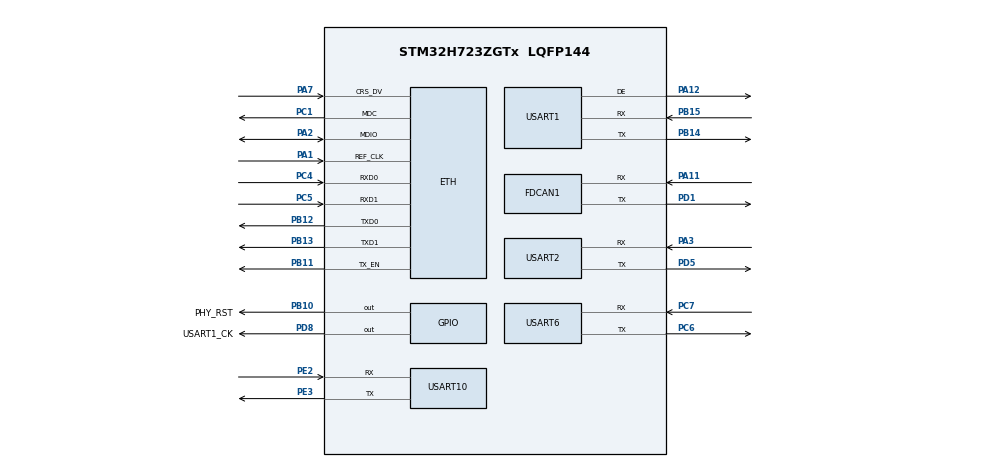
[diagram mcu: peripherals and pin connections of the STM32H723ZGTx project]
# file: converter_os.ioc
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CORTEX_M7.AccessPermission-Cortex_Memory_Protection_Unit_Region0_Settings=MPU_REGION_FULL_ACCESS
CORTEX_M7.AccessPermission-Cortex_Memory_Protection_Unit_Region1_Settings=MPU_REGION_FULL_ACCESS
CORTEX_M7.BaseAddress-Cortex_Memory_Protection_Unit_Region0_Settings=0x30000000
CORTEX_M7.BaseAddress-Cortex_Memory_Protection_Unit_Region1_Settings=0x30000000
CORTEX_M7.CPU_DCache=Enabled
CORTEX_M7.CPU_ICache=Enabled
CORTEX_M7.DisableExec-Cortex_Memory_Protection_Unit_Region0_Settings=MPU_INSTRUCTION_ACCESS_ENABLE
CORTEX_M7.Enable-Cortex_Memory_Protection_Unit_Region0_Settings=MPU_REGION_ENABLE
CORTEX_M7.Enable-Cortex_Memory_Protection_Unit_Region1_Settings=MPU_REGION_ENABLE
CORTEX_M7.Enable-Cortex_Memory_Protection_Unit_Region2_Settings=__NULL
CORTEX_M7.IsBufferable-Cortex_Memory_Protection_Unit_Region1_Settings=MPU_ACCESS_BUFFERABLE
CORTEX_M7.IsCacheable-Cortex_Memory_Protection_Unit_Region0_Settings=MPU_ACCESS_CACHEABLE
CORTEX_M7.IsCacheable-Cortex_Memory_Protection_Unit_Region1_Settings=MPU_ACCESS_NOT_CACHEABLE
CORTEX_M7.IsShareable-Cortex_Memory_Protection_Unit_Region0_Settings=MPU_ACCESS_NOT_SHAREABLE
CORTEX_M7.MPU_Control=MPU_PRIVILEGED_DEFAULT
CORTEX_M7.Size-Cortex_Memory_Protection_Unit_Region0_Settings=MPU_REGION_SIZE_32KB
CORTEX_M7.Size-Cortex_Memory_Protection_Unit_Region1_Settings=MPU_REGION_SIZE_256B
CORTEX_M7.SubRegionDisable-Cortex_Memory_Protection_Unit_Region0_Settings=0
CORTEX_M7.default_mode_Activation=0
Dma.Request0=USART10_RX
Dma.Request1=USART10_TX
Dma.Request2=USART1_RX
Dma.Request3=USART1_TX
Dma.Request4=USART2_RX
Dma.Request5=USART2_TX
Dma.Request6=USART6_RX
Dma.Request7=USART6_TX
Dma.USART10_RX.0.Direction=DMA_PERIPH_TO_MEMORY
Dma.USART10_RX.0.EventEnable=DISABLE
Dma.USART10_RX.0.FIFOMode=DMA_FIFOMODE_DISABLE
Dma.USART10_RX.0.Instance=DMA1_Stream0
Dma.USART10_RX.0.MemDataAlignment=DMA_MDATAALIGN_BYTE
Dma.USART10_RX.0.MemInc=DMA_MINC_ENABLE
Dma.USART10_RX.0.Mode=DMA_CIRCULAR
Dma.USART10_RX.0.PeriphDataAlignment=DMA_PDATAALIGN_BYTE
Dma.USART10_RX.0.PeriphInc=DMA_PINC_DISABLE
Dma.USART10_RX.0.Polarity=HAL_DMAMUX_REQ_GEN_RISING
Dma.USART10_RX.0.Priority=DMA_PRIORITY_LOW
Dma.USART10_RX.0.RequestNumber=1
Dma.USART10_RX.0.SignalID=NONE
Dma.USART10_RX.0.SyncEnable=DISABLE
Dma.USART10_RX.0.SyncPolarity=HAL_DMAMUX_SYNC_NO_EVENT
Dma.USART10_RX.0.SyncRequestNumber=1
Dma.USART10_RX.0.SyncSignalID=NONE
Dma.USART10_TX.1.Direction=DMA_MEMORY_TO_PERIPH
Dma.USART10_TX.1.EventEnable=DISABLE
Dma.USART10_TX.1.FIFOMode=DMA_FIFOMODE_DISABLE
Dma.USART10_TX.1.Instance=DMA1_Stream1
Dma.USART10_TX.1.MemDataAlignment=DMA_MDATAALIGN_BYTE
Dma.USART10_TX.1.MemInc=DMA_MINC_ENABLE
Dma.USART10_TX.1.Mode=DMA_NORMAL
Dma.USART10_TX.1.PeriphDataAlignment=DMA_PDATAALIGN_BYTE
Dma.USART10_TX.1.PeriphInc=DMA_PINC_DISABLE
Dma.USART10_TX.1.Polarity=HAL_DMAMUX_REQ_GEN_RISING
Dma.USART10_TX.1.Priority=DMA_PRIORITY_LOW
Dma.USART10_TX.1.RequestNumber=1
Dma.USART10_TX.1.SignalID=NONE
Dma.USART10_TX.1.SyncEnable=DISABLE
Dma.USART10_TX.1.SyncPolarity=HAL_DMAMUX_SYNC_NO_EVENT
Dma.USART10_TX.1.SyncRequestNumber=1
Dma.USART10_TX.1.SyncSignalID=NONE
Dma.USART1_RX.2.Direction=DMA_PERIPH_TO_MEMORY
Dma.USART1_RX.2.EventEnable=DISABLE
Dma.USART1_RX.2.FIFOMode=DMA_FIFOMODE_DISABLE
Dma.USART1_RX.2.Instance=DMA1_Stream2
Dma.USART1_RX.2.MemDataAlignment=DMA_MDATAALIGN_BYTE
Dma.USART1_RX.2.MemInc=DMA_MINC_ENABLE
Dma.USART1_RX.2.Mode=DMA_CIRCULAR
Dma.USART1_RX.2.PeriphDataAlignment=DMA_PDATAALIGN_BYTE
Dma.USART1_RX.2.PeriphInc=DMA_PINC_DISABLE
Dma.USART1_RX.2.Polarity=HAL_DMAMUX_REQ_GEN_RISING
Dma.USART1_RX.2.Priority=DMA_PRIORITY_LOW
Dma.USART1_RX.2.RequestNumber=1
Dma.USART1_RX.2.SignalID=NONE
Dma.USART1_RX.2.SyncEnable=DISABLE
Dma.USART1_RX.2.SyncPolarity=HAL_DMAMUX_SYNC_NO_EVENT
Dma.USART1_RX.2.SyncRequestNumber=1
Dma.USART1_RX.2.SyncSignalID=NONE
Dma.USART1_TX.3.Direction=DMA_MEMORY_TO_PERIPH
Dma.USART1_TX.3.EventEnable=DISABLE
Dma.USART1_TX.3.FIFOMode=DMA_FIFOMODE_DISABLE
Dma.USART1_TX.3.Instance=DMA1_Stream3
Dma.USART1_TX.3.MemDataAlignment=DMA_MDATAALIGN_BYTE
Dma.USART1_TX.3.MemInc=DMA_MINC_ENABLE
Dma.USART1_TX.3.Mode=DMA_NORMAL
Dma.USART1_TX.3.PeriphDataAlignment=DMA_PDATAALIGN_BYTE
Dma.USART1_TX.3.PeriphInc=DMA_PINC_DISABLE
Dma.USART1_TX.3.Polarity=HAL_DMAMUX_REQ_GEN_RISING
Dma.USART1_TX.3.Priority=DMA_PRIORITY_LOW
Dma.USART1_TX.3.RequestNumber=1
Dma.USART1_TX.3.SignalID=NONE
Dma.USART1_TX.3.SyncEnable=DISABLE
Dma.USART1_TX.3.SyncPolarity=HAL_DMAMUX_SYNC_NO_EVENT
Dma.USART1_TX.3.SyncRequestNumber=1
Dma.USART1_TX.3.SyncSignalID=NONE
Dma.USART2_RX.4.Direction=DMA_PERIPH_TO_MEMORY
Dma.USART2_RX.4.EventEnable=DISABLE
Dma.USART2_RX.4.FIFOMode=DMA_FIFOMODE_DISABLE
Dma.USART2_RX.4.Instance=DMA1_Stream4
Dma.USART2_RX.4.MemDataAlignment=DMA_MDATAALIGN_BYTE
Dma.USART2_RX.4.MemInc=DMA_MINC_ENABLE
Dma.USART2_RX.4.Mode=DMA_CIRCULAR
Dma.USART2_RX.4.PeriphDataAlignment=DMA_PDATAALIGN_BYTE
Dma.USART2_RX.4.PeriphInc=DMA_PINC_DISABLE
Dma.USART2_RX.4.Polarity=HAL_DMAMUX_REQ_GEN_RISING
Dma.USART2_RX.4.Priority=DMA_PRIORITY_LOW
Dma.USART2_RX.4.RequestNumber=1
Dma.USART2_RX.4.SignalID=NONE
Dma.USART2_RX.4.SyncEnable=DISABLE
Dma.USART2_RX.4.SyncPolarity=HAL_DMAMUX_SYNC_NO_EVENT
Dma.USART2_RX.4.SyncRequestNumber=1
Dma.USART2_RX.4.SyncSignalID=NONE
Dma.USART2_TX.5.Direction=DMA_MEMORY_TO_PERIPH
Dma.USART2_TX.5.EventEnable=DISABLE
Dma.USART2_TX.5.FIFOMode=DMA_FIFOMODE_DISABLE
Dma.USART2_TX.5.Instance=DMA1_Stream5
Dma.USART2_TX.5.MemDataAlignment=DMA_MDATAALIGN_BYTE
Dma.USART2_TX.5.MemInc=DMA_MINC_ENABLE
Dma.USART2_TX.5.Mode=DMA_NORMAL
Dma.USART2_TX.5.PeriphDataAlignment=DMA_PDATAALIGN_BYTE
Dma.USART2_TX.5.PeriphInc=DMA_PINC_DISABLE
Dma.USART2_TX.5.Polarity=HAL_DMAMUX_REQ_GEN_RISING
Dma.USART2_TX.5.Priority=DMA_PRIORITY_LOW
Dma.USART2_TX.5.RequestNumber=1
Dma.USART2_TX.5.SignalID=NONE
Dma.USART2_TX.5.SyncEnable=DISABLE
Dma.USART2_TX.5.SyncPolarity=HAL_DMAMUX_SYNC_NO_EVENT
Dma.USART2_TX.5.SyncRequestNumber=1
Dma.USART2_TX.5.SyncSignalID=NONE
Dma.USART6_RX.6.Direction=DMA_PERIPH_TO_MEMORY
Dma.USART6_RX.6.EventEnable=DISABLE
Dma.USART6_RX.6.FIFOMode=DMA_FIFOMODE_DISABLE
Dma.USART6_RX.6.Instance=DMA1_Stream6
Dma.USART6_RX.6.MemDataAlignment=DMA_MDATAALIGN_BYTE
Dma.USART6_RX.6.MemInc=DMA_MINC_ENABLE
Dma.USART6_RX.6.Mode=DMA_CIRCULAR
Dma.USART6_RX.6.PeriphDataAlignment=DMA_PDATAALIGN_BYTE
Dma.USART6_RX.6.PeriphInc=DMA_PINC_DISABLE
Dma.USART6_RX.6.Polarity=HAL_DMAMUX_REQ_GEN_RISING
Dma.USART6_RX.6.Priority=DMA_PRIORITY_LOW
Dma.USART6_RX.6.RequestNumber=1
Dma.USART6_RX.6.SignalID=NONE
Dma.USART6_RX.6.SyncEnable=DISABLE
Dma.USART6_RX.6.SyncPolarity=HAL_DMAMUX_SYNC_NO_EVENT
Dma.USART6_RX.6.SyncRequestNumber=1
Dma.USART6_RX.6.SyncSignalID=NONE
Dma.USART6_TX.7.Direction=DMA_MEMORY_TO_PERIPH
Dma.USART6_TX.7.EventEnable=DISABLE
Dma.USART6_TX.7.FIFOMode=DMA_FIFOMODE_DISABLE
Dma.USART6_TX.7.Instance=DMA1_Stream7
Dma.USART6_TX.7.MemDataAlignment=DMA_MDATAALIGN_BYTE
Dma.USART6_TX.7.MemInc=DMA_MINC_ENABLE
Dma.USART6_TX.7.Mode=DMA_NORMAL
Dma.USART6_TX.7.PeriphDataAlignment=DMA_PDATAALIGN_BYTE
Dma.USART6_TX.7.PeriphInc=DMA_PINC_DISABLE
Dma.USART6_TX.7.Polarity=HAL_DMAMUX_REQ_GEN_RISING
Dma.USART6_TX.7.Priority=DMA_PRIORITY_LOW
Dma.USART6_TX.7.RequestNumber=1
Dma.USART6_TX.7.SignalID=NONE
Dma.USART6_TX.7.SyncEnable=DISABLE
Dma.USART6_TX.7.SyncPolarity=HAL_DMAMUX_SYNC_NO_EVENT
Dma.USART6_TX.7.SyncRequestNumber=1
Dma.USART6_TX.7.SyncSignalID=NONE
ETH.MediaInterface=HAL_ETH_RMII_MODE
FDCAN1.CalculateBaudRateNominal=500000
FDCAN1.CalculateTimeBitNominal=2000
FDCAN1.CalculateTimeQuantumNominal=38.46153846153846
FDCAN1.DataPrescaler=5
FDCAN1.DataSyncJumpWidth=12
FDCAN1.DataTimeSeg1=32
FDCAN1.DataTimeSeg2=16
FDCAN1.NominalPrescaler=5
FDCAN1.NominalSyncJumpWidth=12
FDCAN1.NominalTimeSeg1=39
FDCAN1.NominalTimeSeg2=12
FDCAN1.RxFifo0ElmtsNbr=32
FDCAN1.RxFifo1ElmtsNbr=32
FDCAN1.StdFiltersNbr=1
FDCAN1.TxFifoQueueElmtsNbr=6
Mcu.Family=STM32H7
Mcu.Name=STM32H723ZGTx
Mcu.Package=LQFP144
NVIC.DMA1_Stream0_IRQn=true\:0\:0\:false\:false\:true\:false\:true\:true
NVIC.DMA1_Stream1_IRQn=true\:0\:0\:false\:false\:true\:false\:true\:true
NVIC.DMA1_Stream2_IRQn=true\:0\:0\:false\:false\:true\:false\:true\:true
NVIC.DMA1_Stream3_IRQn=true\:0\:0\:false\:false\:true\:false\:true\:true
NVIC.DMA1_Stream4_IRQn=true\:0\:0\:false\:false\:true\:false\:true\:true
NVIC.DMA1_Stream5_IRQn=true\:0\:0\:false\:false\:true\:false\:true\:true
NVIC.DMA1_Stream6_IRQn=true\:0\:0\:false\:false\:true\:false\:true\:true
NVIC.DMA1_Stream7_IRQn=true\:0\:0\:false\:false\:true\:false\:true\:true
NVIC.ETH_IRQn=true\:0\:0\:false\:false\:true\:true\:true\:true
NVIC.FDCAN1_IT0_IRQn=true\:0\:0\:false\:false\:true\:true\:true\:true
NVIC.FDCAN1_IT1_IRQn=true\:0\:0\:false\:false\:true\:true\:true\:true
NVIC.PriorityGroup=NVIC_PRIORITYGROUP_4
NVIC.TIM2_IRQn=true\:0\:0\:false\:false\:true\:true\:true\:true
NVIC.TIM6_DAC_IRQn=true\:15\:0\:false\:false\:true\:false\:true\:true
NVIC.TimeBase=TIM6_DAC_IRQn
NVIC.TimeBaseIP=TIM6
NVIC.USART10_IRQn=true\:0\:0\:false\:false\:true\:true\:true\:true
NVIC.USART1_IRQn=true\:0\:0\:false\:false\:true\:true\:true\:true
NVIC.USART2_IRQn=true\:0\:0\:false\:false\:true\:true\:true\:true
NVIC.USART6_IRQn=true\:0\:0\:false\:false\:true\:true\:true\:true
PA1.GPIO_Speed=GPIO_SPEED_FREQ_VERY_HIGH
PA1.Mode=RMII
PA1.Signal=ETH_REF_CLK
PA11.Mode=FDCAN_Activate
PA11.Signal=FDCAN1_RX
PA12.Mode=Hardware Flow Control (RS485)
PA12.Signal=USART1_DE
PA2.GPIO_Speed=GPIO_SPEED_FREQ_VERY_HIGH
PA2.Mode=RMII
PA2.Signal=ETH_MDIO
PA3.Mode=Asynchronous
PA3.Signal=USART2_RX
PA7.GPIO_Speed=GPIO_SPEED_FREQ_VERY_HIGH
PA7.Mode=RMII
PA7.Signal=ETH_CRS_DV
PB10.GPIO_Label=PHY_RST
PB10.Signal=GPIO_Output
PB11.GPIO_Speed=GPIO_SPEED_FREQ_VERY_HIGH
PB11.Mode=RMII
PB11.Signal=ETH_TX_EN
PB12.GPIO_Speed=GPIO_SPEED_FREQ_VERY_HIGH
PB12.Mode=RMII
PB12.Signal=ETH_TXD0
PB13.GPIO_Speed=GPIO_SPEED_FREQ_VERY_HIGH
PB13.Mode=RMII
PB13.Signal=ETH_TXD1
PB14.Mode=Asynchronous
PB14.Signal=USART1_TX
PB15.Mode=Asynchronous
PB15.Signal=USART1_RX
PC1.GPIO_Speed=GPIO_SPEED_FREQ_VERY_HIGH
PC1.Mode=RMII
PC1.Signal=ETH_MDC
PC14-OSC32_IN.Mode=LSE-External-Oscillator
PC14-OSC32_IN.Signal=RCC_OSC32_IN
PC15-OSC32_OUT.Mode=LSE-External-Oscillator
PC15-OSC32_OUT.Signal=RCC_OSC32_OUT
PC4.GPIO_Speed=GPIO_SPEED_FREQ_VERY_HIGH
PC4.Mode=RMII
PC4.Signal=ETH_RXD0
PC5.GPIO_Speed=GPIO_SPEED_FREQ_VERY_HIGH
PC5.Mode=RMII
PC5.Signal=ETH_RXD1
PC6.Mode=Asynchronous
PC6.Signal=USART6_TX
PC7.Mode=Asynchronous
PC7.Signal=USART6_RX
PD1.Mode=FDCAN_Activate
PD1.Signal=FDCAN1_TX
PD5.Mode=Asynchronous
PD5.Signal=USART2_TX
PD8.GPIO_Label=USART1_CK
PD8.Signal=GPIO_Output
PE2.Mode=Asynchronous
PE2.Signal=USART10_RX
PE3.Mode=Asynchronous
PE3.Signal=USART10_TX
PH0-OSC_IN.Mode=HSE-External-Oscillator
PH0-OSC_IN.Signal=RCC_OSC_IN
PH1-OSC_OUT.Mode=HSE-External-Oscillator
PH1-OSC_OUT.Signal=RCC_OSC_OUT
ProjectManager.HeapSize=0x800
ProjectManager.StackSize=0x3000
ProjectManager.TargetToolchain=CMake
RCC.ADCFreq_Value=50390625
RCC.APB1Freq_Value=130000000
RCC.APB2Freq_Value=130000000
RCC.APB3Freq_Value=130000000
RCC.APB4Freq_Value=130000000
RCC.CortexFreq_Value=520000000
RCC.D1PPRE=RCC_APB3_DIV2
RCC.D2PPRE1=RCC_APB1_DIV2
RCC.D2PPRE2=RCC_APB2_DIV2
RCC.D3PPRE=RCC_APB4_DIV2
RCC.DIVM1=5
RCC.DIVN1=104
RCC.DIVP1=1
RCC.DIVQ1=4
RCC.HCLKFreq_Value=260000000
RCC.HPRE=RCC_HCLK_DIV2
RCC.PLL2FRACN=0
RCC.PLL3FRACN=0
RCC.PLLFRACN=0
RCC.PLLSourceVirtual=RCC_PLLSOURCE_HSE
RCC.SYSCLKFreq_VALUE=520000000
RCC.SYSCLKSource=RCC_SYSCLKSOURCE_PLLCLK
RCC.USBFreq_Value=130000000
TIM2.Period=999
TIM2.Prescaler=259
USART1.VirtualMode-Asynchronous=VM_ASYNC
USART1.VirtualMode-Hardware\ Flow\ Control\ (RS485)=VM_ASYNC
USART10.VirtualMode-Asynchronous=VM_ASYNC
USART2.VirtualMode-Asynchronous=VM_ASYNC
USART6.VirtualMode-Asynchronous=VM_ASYNC
VP_MEMORYMAP_VS_MEMORYMAP.Mode=CurAppReg
VP_SYS_VS_tim6.Mode=TIM6
VP_TIM2_VS_ClockSourceINT.Mode=Internal
board=custom

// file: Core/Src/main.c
/* USER CODE BEGIN Header */
/**
  ******************************************************************************
  * @file           : main.c
  * @brief          : Main program body
  ******************************************************************************
  * @attention
  *
  * Copyright (c) 2025 STMicroelectronics.
  * All rights reserved.
  *
  * This software is licensed under terms that can be found in the LICENSE file
  * in the root directory of this software component.
  * If no LICENSE file comes with this software, it is provided AS-IS.
  *
  ******************************************************************************
  */
/* USER CODE END Header */
#include "main.h"
#include "dma.h"
#include "eth.h"
#include "fdcan.h"
#include "memorymap.h"
#include "tim.h"
#include "usart.h"
#include "gpio.h"

/* USER CODE BEGIN PD */

void sleep_s(uint32_t s)
{
  tx_thread_sleep(s*1000);
}
void sleep_ms(uint32_t ms)
{
	tx_thread_sleep(ms);
}
void sleep_us(uint32_t us)
{
	tx_thread_sleep(us/1000u);
}

/* USER CODE END PD */

void SystemClock_Config(void);
static void MPU_Config(void);

int main(void)
{

  /* MPU Configuration--------------------------------------------------------*/
  MPU_Config();

  /* Enable the CPU Cache */

  /* Enable I-Cache---------------------------------------------------------*/
  SCB_EnableICache();

  /* Enable D-Cache---------------------------------------------------------*/
  SCB_EnableDCache();

  /* MCU Configuration--------------------------------------------------------*/

  /* Reset of all peripherals, Initializes the Flash interface and the Systick. */
  HAL_Init();

  /* Configure the system clock */
  SystemClock_Config();

  /* Initialize all configured peripherals */
  MX_GPIO_Init();
  MX_DMA_Init();
  MX_FDCAN1_Init();
  MX_USART10_UART_Init();
  MX_USART1_UART_Init();
  MX_USART2_UART_Init();
  MX_USART6_UART_Init();
  MX_TIM2_Init();
  MX_ETH_Init();
  /* USER CODE BEGIN 2 */
  HAL_Delay(500);
  tx_kernel_enter();
  /* USER CODE END 2 */

  /* Infinite loop */
  while (1)
  {

  }
}

void SystemClock_Config(void)
{
  RCC_OscInitTypeDef RCC_OscInitStruct = {0};
  RCC_ClkInitTypeDef RCC_ClkInitStruct = {0};

  /** Supply configuration update enable
  */
  HAL_PWREx_ConfigSupply(PWR_LDO_SUPPLY);

  /** Configure the main internal regulator output voltage
  */
  __HAL_PWR_VOLTAGESCALING_CONFIG(PWR_REGULATOR_VOLTAGE_SCALE0);

  while(!__HAL_PWR_GET_FLAG(PWR_FLAG_VOSRDY)) {}

  /** Initializes the RCC Oscillators according to the specified parameters
  * in the RCC_OscInitTypeDef structure.
  */
  RCC_OscInitStruct.OscillatorType = RCC_OSCILLATORTYPE_HSE;
  RCC_OscInitStruct.HSEState = RCC_HSE_ON;
  RCC_OscInitStruct.PLL.PLLState = RCC_PLL_ON;
  RCC_OscInitStruct.PLL.PLLSource = RCC_PLLSOURCE_HSE;
  RCC_OscInitStruct.PLL.PLLM = 5;
  RCC_OscInitStruct.PLL.PLLN = 104;
  RCC_OscInitStruct.PLL.PLLP = 1;
  RCC_OscInitStruct.PLL.PLLQ = 4;
  RCC_OscInitStruct.PLL.PLLR = 2;
  RCC_OscInitStruct.PLL.PLLRGE = RCC_PLL1VCIRANGE_2;
  RCC_OscInitStruct.PLL.PLLVCOSEL = RCC_PLL1VCOWIDE;
  RCC_OscInitStruct.PLL.PLLFRACN = 0;
  if (HAL_RCC_OscConfig(&RCC_OscInitStruct) != HAL_OK)
  {
    Error_Handler();
  }

  /** Initializes the CPU, AHB and APB buses clocks
  */
  RCC_ClkInitStruct.ClockType = RCC_CLOCKTYPE_HCLK|RCC_CLOCKTYPE_SYSCLK
                              |RCC_CLOCKTYPE_PCLK1|RCC_CLOCKTYPE_PCLK2
                              |RCC_CLOCKTYPE_D3PCLK1|RCC_CLOCKTYPE_D1PCLK1;
  RCC_ClkInitStruct.SYSCLKSource = RCC_SYSCLKSOURCE_PLLCLK;
  RCC_ClkInitStruct.SYSCLKDivider = RCC_SYSCLK_DIV1;
  RCC_ClkInitStruct.AHBCLKDivider = RCC_HCLK_DIV2;
  RCC_ClkInitStruct.APB3CLKDivider = RCC_APB3_DIV2;
  RCC_ClkInitStruct.APB1CLKDivider = RCC_APB1_DIV2;
  RCC_ClkInitStruct.APB2CLKDivider = RCC_APB2_DIV2;
  RCC_ClkInitStruct.APB4CLKDivider = RCC_APB4_DIV2;

  if (HAL_RCC_ClockConfig(&RCC_ClkInitStruct, FLASH_LATENCY_3) != HAL_OK)
  {
    Error_Handler();
  }
}

 /* MPU Configuration */

void MPU_Config(void)
{
  MPU_Region_InitTypeDef MPU_InitStruct = {0};

  /* Disables the MPU */
  HAL_MPU_Disable();

  /** Initializes and configures the Region and the memory to be protected
  */
  MPU_InitStruct.Enable = MPU_REGION_ENABLE;
  MPU_InitStruct.Number = MPU_REGION_NUMBER0;
  MPU_InitStruct.BaseAddress = 0x30000000;
  MPU_InitStruct.Size = MPU_REGION_SIZE_32KB;
  MPU_InitStruct.SubRegionDisable = 0;
  MPU_InitStruct.TypeExtField = MPU_TEX_LEVEL0;
  MPU_InitStruct.AccessPermission = MPU_REGION_FULL_ACCESS;
  MPU_InitStruct.DisableExec = MPU_INSTRUCTION_ACCESS_ENABLE;
  MPU_InitStruct.IsShareable = MPU_ACCESS_NOT_SHAREABLE;
  MPU_InitStruct.IsCacheable = MPU_ACCESS_CACHEABLE;
  MPU_InitStruct.IsBufferable = MPU_ACCESS_NOT_BUFFERABLE;

  HAL_MPU_ConfigRegion(&MPU_InitStruct);

  /** Initializes and configures the Region and the memory to be protected
  */
  MPU_InitStruct.Number = MPU_REGION_NUMBER1;
  MPU_InitStruct.Size = MPU_REGION_SIZE_256B;
  MPU_InitStruct.SubRegionDisable = 0x0;
  MPU_InitStruct.IsCacheable = MPU_ACCESS_NOT_CACHEABLE;
  MPU_InitStruct.IsBufferable = MPU_ACCESS_BUFFERABLE;

  HAL_MPU_ConfigRegion(&MPU_InitStruct);
  /* Enables the MPU */
  HAL_MPU_Enable(MPU_PRIVILEGED_DEFAULT);

}

void HAL_TIM_PeriodElapsedCallback(TIM_HandleTypeDef *htim)
{
  if (htim->Instance == TIM6)
  {
    HAL_IncTick();
  }
}

void Error_Handler(void)
{
  __disable_irq();
  while (1)
  {
  }
}
